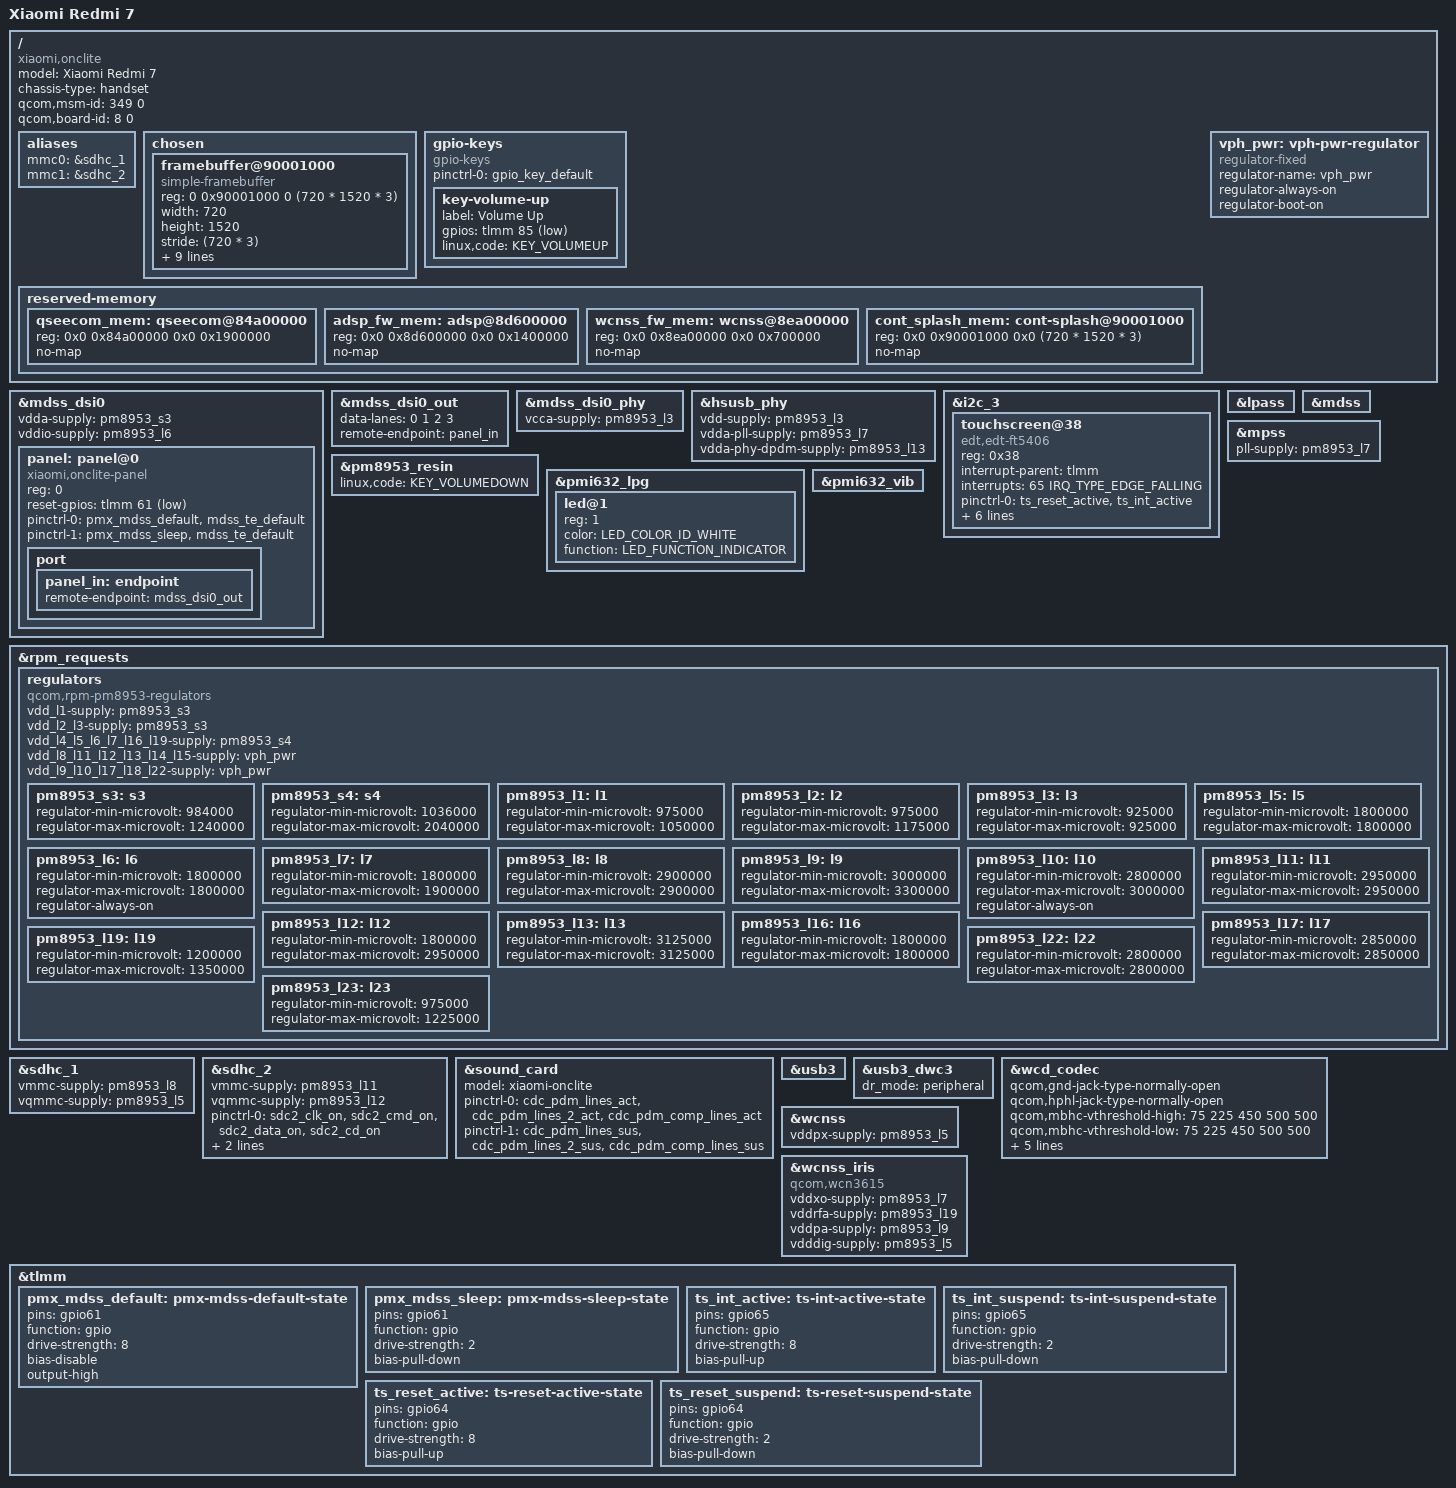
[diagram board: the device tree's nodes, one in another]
// SPDX-License-Identifier: BSD-3-Clause
/*
 * Copyright (c) 2023, Barnabas Czeman
 */
/dts-v1/;

#include <dt-bindings/leds/common.h>
#include "sdm632.dtsi"
#include "pm8953.dtsi"
#include "pmi632.dtsi"

/delete-node/ &cont_splash_mem;
/delete-node/ &wcnss_fw_mem;
/delete-node/ &adsp_fw_mem;
/delete-node/ &qseecom_mem;

/ {
	model = "Xiaomi Redmi 7";
	compatible = "xiaomi,onclite", "qcom,sdm632";
	chassis-type = "handset";
	qcom,msm-id = <349 0>;
	qcom,board-id = <8 0>;

	aliases {
		mmc0 = &sdhc_1;
		mmc1 = &sdhc_2;
	};

	chosen {
		#address-cells = <2>;
		#size-cells = <2>;
		ranges;

		framebuffer@90001000 {
			compatible = "simple-framebuffer";
			reg = <0 0x90001000 0 (720 * 1520 * 3)>;

			width = <720>;
			height = <1520>;
			stride = <(720 * 3)>;
			format = "r8g8b8";

			power-domains = <&gcc MDSS_GDSC>;

			clocks = <&gcc GCC_MDSS_AHB_CLK>,
				 <&gcc GCC_MDSS_AXI_CLK>,
				 <&gcc GCC_MDSS_VSYNC_CLK>,
				 <&gcc GCC_MDSS_MDP_CLK>,
				 <&gcc GCC_MDSS_BYTE0_CLK>,
				 <&gcc GCC_MDSS_PCLK0_CLK>,
				 <&gcc GCC_MDSS_ESC0_CLK>;
		};
	};

	gpio-keys {
		compatible = "gpio-keys";

		pinctrl-0 = <&gpio_key_default>;
		pinctrl-names = "default";

		key-volume-up {
			label = "Volume Up";
			gpios = <&tlmm 85 GPIO_ACTIVE_LOW>;
			linux,code = <KEY_VOLUMEUP>;
		};
	};

	reserved-memory {
		qseecom_mem: qseecom@84a00000 {
			reg = <0x0 0x84a00000 0x0 0x1900000>;
			no-map;
		};

		adsp_fw_mem: adsp@8d600000 {
			reg = <0x0 0x8d600000 0x0 0x1400000>;
			no-map;
		};

		wcnss_fw_mem: wcnss@8ea00000 {
			reg = <0x0 0x8ea00000 0x0 0x700000>;
			no-map;
		};

		cont_splash_mem: cont-splash@90001000 {
			reg = <0x0 0x90001000 0x0 (720 * 1520 * 3)>;
			no-map;
		};
	};

	vph_pwr: vph-pwr-regulator {
		compatible = "regulator-fixed";
		regulator-name = "vph_pwr";
		regulator-always-on;
		regulator-boot-on;
	};
};

&mdss_dsi0 {
	vdda-supply = <&pm8953_s3>;
	vddio-supply = <&pm8953_l6>;
	status = "okay";

	panel: panel@0 {
		compatible = "xiaomi,onclite-panel";
		reg = <0>;

		reset-gpios = <&tlmm 61 GPIO_ACTIVE_LOW>;

		pinctrl-0 = <&pmx_mdss_default &mdss_te_default>;
		pinctrl-1 = <&pmx_mdss_sleep &mdss_te_default>;
		pinctrl-names = "default", "sleep";

		// Downstream:
		// lab-supply = <&lcdb_ldo_vreg>;
		// ibb-supply = <&lcdb_ncp_vreg>;

		// lcdb driver is not yet in mainline
		// vsp-supply = <>;
		// vsn-supply = <>;

		port {
			panel_in: endpoint {
				remote-endpoint = <&mdss_dsi0_out>;
			};
		};
	};
};

&mdss_dsi0_out {
	data-lanes = <0 1 2 3>;
	remote-endpoint = <&panel_in>;
};

&mdss_dsi0_phy {
	vcca-supply = <&pm8953_l3>;

	status = "okay";
};

&hsusb_phy {
	vdd-supply = <&pm8953_l3>;
	vdda-pll-supply = <&pm8953_l7>;
	vdda-phy-dpdm-supply = <&pm8953_l13>;

	status = "okay";
};

&i2c_3 {
	status = "okay";

	touchscreen@38 {
		compatible = "edt,edt-ft5406";
		reg = <0x38>;

		interrupt-parent = <&tlmm>;
		interrupts = <65 IRQ_TYPE_EDGE_FALLING>;

		pinctrl-0 = <&ts_reset_active &ts_int_active>;
		pinctrl-1 = <&ts_reset_suspend &ts_int_suspend>;
		pinctrl-names = "default", "sleep";

		reset-gpios = <&tlmm 64 GPIO_ACTIVE_LOW>;

		iovcc-supply = <&pm8953_l6>;
		vcc-supply = <&pm8953_l10>;

		touchscreen-size-x = <720>;
		touchscreen-size-y = <1520>;

		status = "okay";
	};
};

&lpass {
	status = "okay";
};

&mdss {
	status = "okay";
};

&mpss {
	pll-supply = <&pm8953_l7>;

	status = "okay";
};

&pm8953_resin {
	linux,code = <KEY_VOLUMEDOWN>;

	status = "okay";
};

&pmi632_lpg {
	status = "okay";

	#address-cells = <1>;
	#size-cells = <0>;

	led@1 {
		reg = <1>;
		color = <LED_COLOR_ID_WHITE>;
		function = LED_FUNCTION_INDICATOR;
	};
};

&pmi632_vib {
	status = "okay";
};

&rpm_requests {
	regulators {
		compatible = "qcom,rpm-pm8953-regulators";

		vdd_l1-supply = <&pm8953_s3>;
		vdd_l2_l3-supply = <&pm8953_s3>;
		vdd_l4_l5_l6_l7_l16_l19-supply = <&pm8953_s4>;
		vdd_l8_l11_l12_l13_l14_l15-supply = <&vph_pwr>;
		vdd_l9_l10_l17_l18_l22-supply = <&vph_pwr>;

		pm8953_s3: s3 {
			regulator-min-microvolt = <984000>;
			regulator-max-microvolt = <1240000>;
		};

		pm8953_s4: s4 {
			regulator-min-microvolt = <1036000>;
			regulator-max-microvolt = <2040000>;
		};

		pm8953_l1: l1 {
			regulator-min-microvolt = <975000>;
			regulator-max-microvolt = <1050000>;
		};

		pm8953_l2: l2 {
			regulator-min-microvolt = <975000>;
			regulator-max-microvolt = <1175000>;
		};

		pm8953_l3: l3 {
			regulator-min-microvolt = <925000>;
			regulator-max-microvolt = <925000>;
		};

		pm8953_l5: l5 {
			regulator-min-microvolt = <1800000>;
			regulator-max-microvolt = <1800000>;
		};

		pm8953_l6: l6 {
			regulator-min-microvolt = <1800000>;
			regulator-max-microvolt = <1800000>;
			regulator-always-on;
		};

		pm8953_l7: l7 {
			regulator-min-microvolt = <1800000>;
			regulator-max-microvolt = <1900000>;
		};

		pm8953_l8: l8 {
			regulator-min-microvolt = <2900000>;
			regulator-max-microvolt = <2900000>;
		};

		pm8953_l9: l9 {
			regulator-min-microvolt = <3000000>;
			regulator-max-microvolt = <3300000>;
		};

		pm8953_l10: l10 {
			regulator-min-microvolt = <2800000>;
			regulator-max-microvolt = <3000000>;
			regulator-always-on;
		};

		pm8953_l11: l11 {
			regulator-min-microvolt = <2950000>;
			regulator-max-microvolt = <2950000>;
		};

		pm8953_l12: l12 {
			regulator-min-microvolt = <1800000>;
			regulator-max-microvolt = <2950000>;
		};

		pm8953_l13: l13 {
			regulator-min-microvolt = <3125000>;
			regulator-max-microvolt = <3125000>;
		};

		pm8953_l16: l16 {
			regulator-min-microvolt = <1800000>;
			regulator-max-microvolt = <1800000>;
		};

		pm8953_l17: l17 {
			regulator-min-microvolt = <2850000>;
			regulator-max-microvolt = <2850000>;
		};

		pm8953_l19: l19 {
			regulator-min-microvolt = <1200000>;
			regulator-max-microvolt = <1350000>;
		};

		pm8953_l22: l22 {
			regulator-min-microvolt = <2800000>;
			regulator-max-microvolt = <2800000>;
		};

		pm8953_l23: l23 {
			regulator-min-microvolt = <975000>;
			regulator-max-microvolt = <1225000>;
		};
	};
};

&sdhc_1 {
	vmmc-supply = <&pm8953_l8>;
	vqmmc-supply = <&pm8953_l5>;

	status = "okay";
};

&sdhc_2 {
	vmmc-supply = <&pm8953_l11>;
	vqmmc-supply = <&pm8953_l12>;

	pinctrl-0 = <&sdc2_clk_on &sdc2_cmd_on &sdc2_data_on &sdc2_cd_on>;
	pinctrl-1 = <&sdc2_clk_off &sdc2_cmd_off &sdc2_data_off &sdc2_cd_off>;
	pinctrl-names = "default", "sleep";

	status = "okay";
};

&sound_card {
	model = "xiaomi-onclite";

	pinctrl-0 = <&cdc_pdm_lines_act &cdc_pdm_lines_2_act &cdc_pdm_comp_lines_act>;
	pinctrl-1 = <&cdc_pdm_lines_sus &cdc_pdm_lines_2_sus &cdc_pdm_comp_lines_sus>;
	pinctrl-names = "default", "sleep";

	status = "okay";
};

&usb3 {
	status = "okay";
};

&usb3_dwc3 {
	dr_mode = "peripheral";
};

&wcd_codec {
	qcom,gnd-jack-type-normally-open;
	qcom,hphl-jack-type-normally-open;
	qcom,mbhc-vthreshold-high = <75 225 450 500 500>;
	qcom,mbhc-vthreshold-low = <75 225 450 500 500>;
	qcom,micbias1-ext-cap;
	qcom,micbias2-ext-cap;

	vdd-cdc-io-supply = <&pm8953_l5>;
	vdd-cdc-tx-rx-cx-supply = <&pm8953_s4>;
	vdd-micbias-supply = <&pm8953_l13>;

	status = "okay";
};

&wcnss {
	vddpx-supply = <&pm8953_l5>;

	status = "okay";
};

&wcnss_iris {
	compatible = "qcom,wcn3615", "qcom,wcn3620";

	vddxo-supply = <&pm8953_l7>;
	vddrfa-supply = <&pm8953_l19>;
	vddpa-supply = <&pm8953_l9>;
	vdddig-supply = <&pm8953_l5>;
};

&tlmm {
	pmx_mdss_default: pmx-mdss-default-state {
		pins = "gpio61";
		function = "gpio";
		drive-strength = <8>;
		bias-disable;
		output-high;
	};

	pmx_mdss_sleep: pmx-mdss-sleep-state {
		pins = "gpio61";
		function = "gpio";
		drive-strength = <2>;
		bias-pull-down;
	};

	ts_int_active: ts-int-active-state {
		pins = "gpio65";
		function = "gpio";
		drive-strength = <8>;
		bias-pull-up;
	};

	ts_int_suspend: ts-int-suspend-state {
		pins = "gpio65";
		function = "gpio";
		drive-strength = <2>;
		bias-pull-down;
	};

	ts_reset_active: ts-reset-active-state {
		pins = "gpio64";
		function = "gpio";
		drive-strength = <8>;
		bias-pull-up;
	};

	ts_reset_suspend: ts-reset-suspend-state {
		pins = "gpio64";
		function = "gpio";
		drive-strength = <2>;
		bias-pull-down;
	};
};
